# STM32H7B0 register map
File version: 2.3
CPU: CM7 r0p1, little endian, MPU, FPU, 4 interrupt priority bits
Registers are 32-bit, read-write, reset 0x0 unless marked. A register's access mark holds for its fields unless they carry their own. Offsets are from the block's base; [hi:lo] are bit positions; lines under a group give offsets from that group; {n}, {i} and the like mark numbered series.

## DBGMCU — Microcontroller Debug Unit
Base 0x5C001000
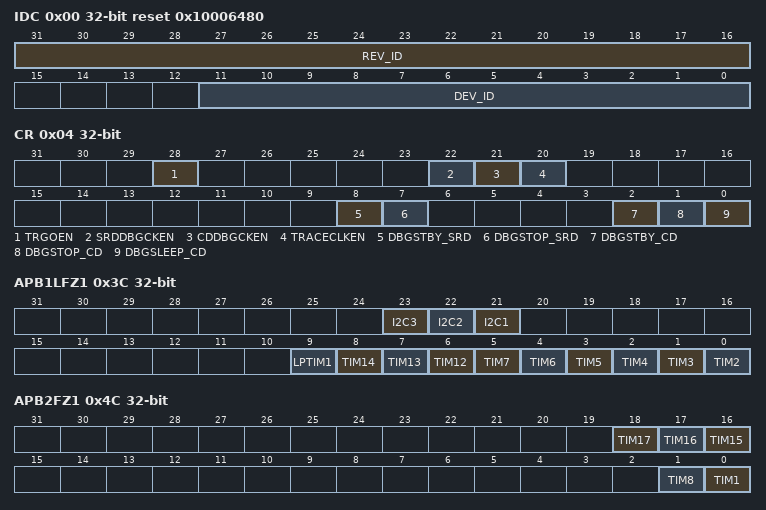
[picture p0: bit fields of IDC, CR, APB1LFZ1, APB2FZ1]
0x00 IDC ro reset 0x10006480 — DBGMCU Identity Code Register
  [31:16] REV_ID — Revision
  [11:0] DEV_ID — Device ID
0x04 CR — DBGMCU Configuration Register
  [28] TRGOEN — External trigger output enable
  [22] SRDDBGCKEN — SmartRun domain debug clock enable
  [21] CDDBGCKEN — CPU domain debug clock enable
  [20] TRACECLKEN — Trace port clock enable
  [8] DBGSTBY_SRD — debug in SmartRun domain Standby mode
  [7] DBGSTOP_SRD — debug in SmartRun domain Stop mode
  [2] DBGSTBY_CD — Allow D1 domain debug in Standby mode
  [1] DBGSTOP_CD — Allow D1 domain debug in Stop mode
  [0] DBGSLEEP_CD — Allow D1 domain debug in Sleep mode
0x34 APB3FZ1 — DBGMCU APB3 peripheral freeze register
  [6] WWDG — WWDG stop in debug
0x3C APB1LFZ1 — DBGMCU APB1L peripheral freeze register
  [23] I2C3 — I2C3 SMBUS timeout stop in debug
  [22] I2C2 — I2C2 SMBUS timeout stop in debug
  [21] I2C1 — I2C1 SMBUS timeout stop in debug
  [9] LPTIM1 — LPTIM1 stop in debug
  [8] TIM14 — TIM14 stop in debug
  [7] TIM13 — TIM13 stop in debug
  [6] TIM12 — TIM12 stop in debug
  [n-2] TIM{n} (n=2..7) — TIM{n} stop in debug
0x4C APB2FZ1 — DBGMCU APB2 peripheral freeze register
  [18] TIM17 — TIM17 stop in debug
  [17] TIM16 — TIM16 stop in debug
  [16] TIM15 — TIM15 stop in debug
  [1] TIM8 — TIM8 stop in debug
  [0] TIM1 — TIM1 stop in debug
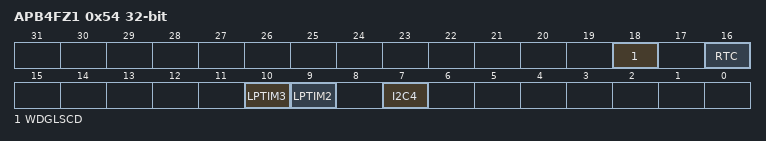
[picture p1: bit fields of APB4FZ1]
0x54 APB4FZ1 — DBGMCU APB4 peripheral freeze register
  [18] WDGLSCD — LS watchdog for CPU domain stop in debug
  [16] RTC — RTC stop in debug
  [10] LPTIM3 — LPTIM3 stop in debug
  [9] LPTIM2 — LPTIM2 stop in debug
  [7] I2C4 — I2C4 SMBUS timeout stop in debug

## SYSCFG — System configuration controller
Base 0x58000400
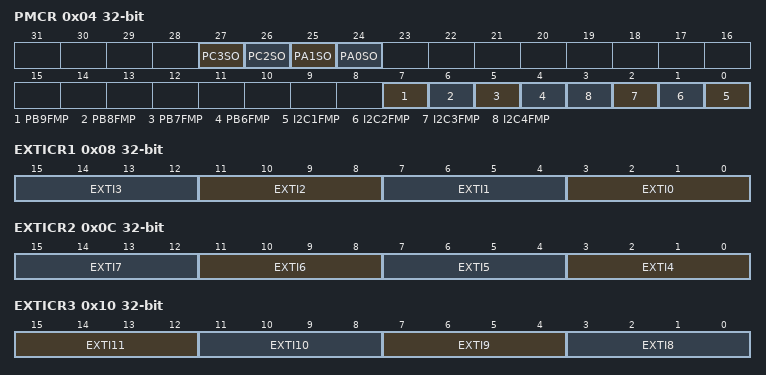
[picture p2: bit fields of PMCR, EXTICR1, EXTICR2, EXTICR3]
0x04 PMCR — peripheral mode configuration register
  [27] PC3SO — PC3 Switch Open
  [26] PC2SO — PC2 Switch Open
  [25] PA1SO — PA1 Switch Open
  [24] PA0SO — PA0 Switch Open
  [7] PB9FMP — PB(9) Fm+
  [6] PB8FMP — PB(8) Fast Mode Plus
  [5] PB7FMP — PB(7) Fast Mode Plus
  [4] PB6FMP — PB(6) Fm+
  [n-1] I2C{n}FMP (n=1..4) — I2C{n} Fm+
0x08 EXTICR1 — external interrupt configuration register 1
  [4n+3:4n] EXTI{n} (n=0..3) — EXTI x configuration (x = 0 to 3)
0x0C EXTICR2 — external interrupt configuration register 2
  [4n-13:4n-16] EXTI{n} (n=4..7) — EXTI x configuration (x = 4 to 7)
0x10 EXTICR3 — external interrupt configuration register 3
  [15:12] EXTI11 — EXTI x configuration (x = 8 to 11)
  [11:8] EXTI10
  [7:4] EXTI9 — EXTI x configuration (x = 8 to 11)
  [3:0] EXTI8 — EXTI x configuration (x = 8 to 11)
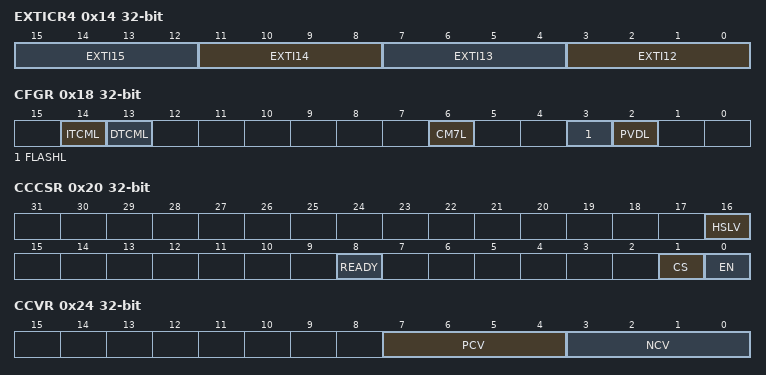
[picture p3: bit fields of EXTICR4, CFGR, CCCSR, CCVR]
0x14 EXTICR4 — external interrupt configuration register 4
  [4n-45:4n-48] EXTI{n} (n=12..15) — EXTI x configuration (x = 12 to 15)
0x18 CFGR — SYSCFG timer break lockup register
  [14] ITCML — ITCM double ECC error signal lock
  [13] DTCML — D1TCM or D0TCM double ECC error signal lock
  [6] CM7L — Cortex-M7 LOCKUP (HardFault) output enable bit
  [3] FLASHL — Flash double ECC error lock bit
  [2] PVDL — PVD lock enable bit.
0x20 CCCSR — compensation cell control/status register
  [16] HSLV — High-speed at low-voltage
  [8] READY — Compensation cell ready flag
  [1] CS — Code selection
  [0] EN — enable
0x24 CCVR ro — SYSCFG compensation cell value register
  [7:4] PCV — PMOS compensation value
  [3:0] NCV — NMOS compensation value
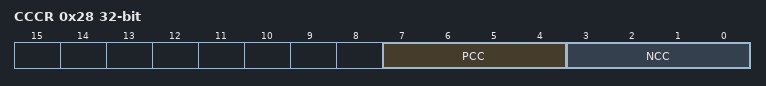
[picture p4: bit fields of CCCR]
0x28 CCCR — SYSCFG compensation cell code register
  [7:4] PCC — PMOS compensation code
  [3:0] NCC — NMOS compensation code

## RAMECC — ECC controller is associated to each RAM area
Base 0x52009000
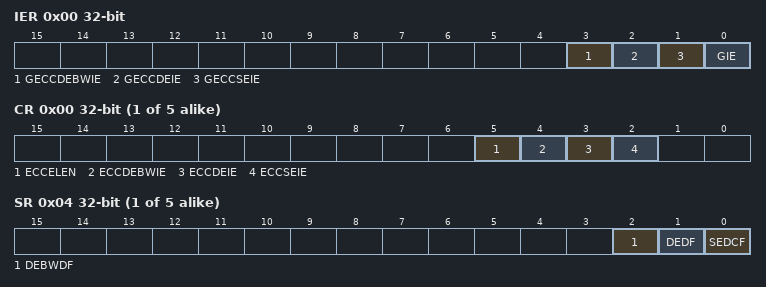
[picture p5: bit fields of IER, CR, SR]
0x00 IER — RAMECC interrupt enable register
  [3] GECCDEBWIE — Global ECC double error on byte write (BW) interrupt enable
  [2] GECCDEIE — Global ECC double error interrupt enable
  [1] GECCSEIE — Global ECC single error interrupt enable
  [0] GIE — Global interrupt enable
{0x0+0x20*i} M{i} (i=1..5) group — Cluster M{i}, containing M?CR, M?SR, M?FAR, M?FDRL, M?FDRH, M?FECR
  0x00 CR — RAMECC monitor x configuration register
    [5] ECCELEN — ECC error latching enable
    [4] ECCDEBWIE — ECC double error on byte write (BW) interrupt enable
    [3] ECCDEIE — ECC double error interrupt enable
    [2] ECCSEIE — ECC single error interrupt enable
  0x04 SR — RAMECC monitor x status register
    [2] DEBWDF — ECC double error on byte write (BW) detected flag
    [1] DEDF — ECC double error detected flag
    [0] SEDCF — ECC single error detected and corrected flag
  0x08 FAR ro — RAMECC monitor x failing address register
    [31:0] FADD — ECC error failing address
  0x0C FDRL ro — RAMECC monitor x failing data low register
    [31:0] FDATAL — Failing data low
  0x10 FDRH ro — RAMECC monitor x failing data high register
    [31:0] FDATAH — Failing data high (64-bit memory)
  0x14 FECR ro — RAMECC monitor x failing ECC error code register
    [31:0] FEC — Failing error code

## WWDG
Base 0x50003000
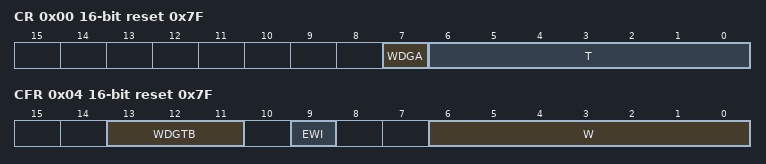
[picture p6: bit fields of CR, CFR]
0x00 CR 16-bit reset 0x7F — Control register
  [7] WDGA — Activation bit This bit is set by software and only cleared by hardware after a reset. When WDGA=1, the watchdog can generate a reset.
    0=Disabled (Watchdog disabled); 1=Enabled (Watchdog enabled)
  [6:0] T — 7-bit counter (MSB to LSB) These bits contain the value of the watchdog counter. It is decremented every (4096 x 2WDGTB[1:0]) PCLK cycles. A reset is produced when it is decremented from 0x40 to 0x3F (T6 becomes cleared).
0x04 CFR 16-bit reset 0x7F — Configuration register
  [13:11] WDGTB — Timer base The time base of the prescaler can be modified as follows:
    0=Div1 (Counter clock (PCLK1 div 4096) div 1); 1=Div2 (Counter clock (PCLK1 div 4096) div 2); 2=Div4 (Counter clock (PCLK1 div 4096) div 4); 3=Div8 (Counter clock (PCLK1 div 4096) div 8); 4=Div16 (Counter clock (PCLK1 div 4096) div 16); 5=Div32 (Counter clock (PCLK1 div 4096) div 32); 6=Div64 (Counter clock (PCLK1 div 4096) div 64); 7=Div128 (Counter clock (PCLK1 div 4096) div 128)
  [9] EWI — Early wakeup interrupt When set, an interrupt occurs whenever the counter reaches the value 0x40. This interrupt is only cleared by hardware after a reset.
    on write: 1=Enable (interrupt occurs whenever the counter reaches the value 0x40)
  [6:0] W — 7-bit window value These bits contain the window value to be compared to the downcounter.
0x08 SR 16-bit — Status register
  [0] EWIF write-0-clears — Early wakeup interrupt flag This bit is set by hardware when the counter has reached the value 0x40. It must be cleared by software by writing 0. A write of 1 has no effect. This bit is also set if the interrupt is not enabled.
    on read: 0=Finished (The EWI Interrupt Service Routine has been serviced); 1=Pending (The EWI Interrupt Service Routine has been triggered) | on write: 0=Finished (The EWI Interrupt Service Routine has been serviced)
